# MEC1721N_B0_LJ register map
Vendor: Microchip Technology; Series: MEC172x; File version: 0
CPU: CM4 r1p0, little endian, MPU, FPU, 3 interrupt priority bits, 172 interrupts
Registers are 32-bit, read-write, reset 0x0 unless marked. A register's access mark holds for its fields unless they carry their own. Offsets are from the block's base; [hi:lo] are bit positions; {n}, {i} and the like mark numbered series.

## VBAT_RAM — The VBAT RAM is operational while the main power rail is operational, and will retain its values powered by battery power while the main rail is unpowered.
Base 0x4000A800
{0x0+4i} MEM[{i}] (i=0..31) — 32-bits of VBAT powered RAM.

## VBAT — The VBAT Register Bank block is a block implemented for miscellaneous battery-backed registers.
Base 0x4000A400
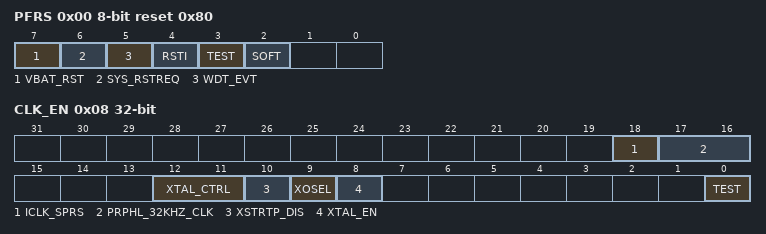
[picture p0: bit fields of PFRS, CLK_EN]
0x00 PFRS 8-bit reset 0x80 — The Power-Fail and Reset Status Register collects and retains the VBAT RST and WDT event status when VCC1 is unpowered.
  [7] VBAT_RST — The VBAT RST bit is set to '1' by hardware when a RESET_VBAT is detected. This is the register default value. To clear VBAT RST EC firmware must write a '1' to this bit; writing a '0' to VBAT RST has no affect.(R/WC)
  [6] SYS_RSTREQ — This bit is set to '1b' if a RESET_SYS was triggered by an ARM SYSRESETREQ event. This bit is cleared to '0b' when written with a '1b'; writes of a '0b' have no effect. (R/WC)
  [5] WDT_EVT — This bit is set to '1b' if a RESET_SYS was triggered by a Watchdog Timer event. This bit is cleared to '0b' when written with a '1b'; writes of a '0b' have no effect. (R/WC)
  [4] RSTI — This bit is set to '1b' if a RESET_SYS was triggered by a low signal on the RESETI# input pin. This bit is cleared to '0b' when written with a '1b'; writes of a '0b' have no effect. (R/WC)
  [3] TEST
  [2] SOFT — This bit is set to '1b' if a was triggered by an assertion of the SOFT_SYS_RESET bit in the System Reset Register. This bit is cleared to '0b' when written with a '1b'; writes of a '0b' have no effect. (R/WC)
0x08 CLK_EN — 32KHz Clock Enable Register
  [18] ICLK_SPRS — When enabled the Internal 32kHz VBAT clock source is suppressed (disabled) when VTR goes down.
  [17:16] PRPHL_32KHZ_CLK — MUX Select for the source of the 32kHz Peripheral Clock.
  [12:11] XTAL_CTRL — XTAL Gain Control 0 = Original Gain. 1 or 2=Gain reduced. 3= Gain is smallest.
  [10] XSTRTP_DIS — XTAL Startup Disable When enabled the XTAL, in Dual-Ended Mode, will enter a low power mode.
  [9] XOSEL — This bit selects between a single-ended clock source for the crystal oscillator or an external parallel crystal. 1= the Crystal Oscillator is driven by a single-ended 32KHz clock source connected to the XTAL2 pin. 0= the Crystal Oscillator requires a 32KHz parallel resonant crystal connected between the XTAL1 and XTAL2 pins (default).
  [8] XTAL_EN — XTAL Enable Enables/Starts the XTAL clock operation.
  [0] TEST — This is a test bit and must not be modified.
0x20 MCNT_LO — MONOTONIC COUNTER
  [31:0] CNTR — Read-only register that increments by 1 every time it is read. It is reset to 0 on a VBAT Power On Reset.
0x24 MCNT_HI — COUNTER HIWORD
  [31:0] CNTR — Thirty-two bit read/write register. If software sets this register to an incrementing value, based on an external non-volatile store, this register may be combined with the Monotonic Counter Register to form a 64-bit monotonic counter.
0x34 EMDRST_DBNC_EN — Embedded Reset Debouce Enable.
  [0] DBNC_EN — Embedded Reset Debouce Enable. 0 = Disable 1 = Enable

## ESPI_SCRATCH — 32 Byte ESPI Test Register
Base 0x400FBC00
{0x0+4i} SCRATCH{i} (i=0..7)
  [31:0] SCR{i} — This field has no functionality other than storage. This register is aliased to ESPI Config Scratch Register.

## SAFCOMM — This register contains one bit PREFETCH_EN that should be set to '1' during initialization, to enable Prefetch Mode operation in SAFS Mode. Prefetch Mode allows overlapped anticipatory reading of information from Flash during the eSPI delivery of previously-read data to the Host Chipset. If enabled, Prefetching is invoked during consecutive Reads that are 64 bytes in length and from consecutive 64-byte aligned Flash addresses. With roughly equal clock rates on eSPI and SPI, these features together can approximately double the effective bandwidth of consecutive Flash reads performed over eSPI. In SAFS operation (SAF_MODE_ENABLE bit = 1) attempted accesses by EC firmware to this register are blocked.
Base 0x40071000
0x2B8 SAF_MODE — This register contains one bit PREFETCH_EN that should be set to '1' during initialization, to enable Prefetch Mode operation in SAFS Mode.
  [0] PREFETCH_EN — 1= Allow Prefetching from Flash devices, and use the bits CS0_PREFETCH_OPT_EN and CS1_PREFETCH_OPT_EN to select any additional optimization. 0= Do not perform Prefetches from Flash devices
